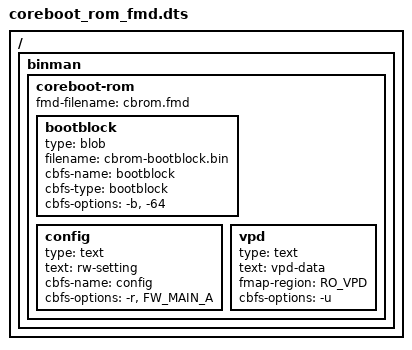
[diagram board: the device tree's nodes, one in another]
// SPDX-License-Identifier: GPL-2.0+

/dts-v1/;

/ {
	#address-cells = <1>;
	#size-cells = <1>;

	binman {
		coreboot-rom {
			fmd-filename = "cbrom.fmd";

			bootblock {
				type = "blob";
				filename = "cbrom-bootblock.bin";
				cbfs-name = "bootblock";
				cbfs-type = "bootblock";
				cbfs-options = "-b", "-64";
			};
			config {
				type = "text";
				text = "rw-setting";
				cbfs-name = "config";
				cbfs-options = "-r", "FW_MAIN_A";
			};
			vpd {
				type = "text";
				text = "vpd-data";
				fmap-region = "RO_VPD";
				cbfs-options = "-u";
			};
		};
	};
};
